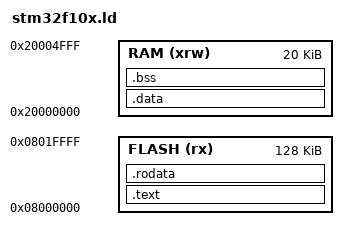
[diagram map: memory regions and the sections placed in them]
/* 指定内存区域 */
MEMORY
{
    FLASH (rx)  : ORIGIN = 0x08000000, LENGTH = 128K
    RAM (xrw)   : ORIGIN = 0x20000000, LENGTH = 20K
}

SECTIONS {

    .text      :
    {
        . = ALIGN(4);
        *start.o (.text)
        *main.o (.text)
        *(.text)
    } > FLASH

    .rodata :
    {
        . = ALIGN(4);
        *(.rodata)         /* .rodata sections (constants, strings, etc.) */
        *(.rodata*)        /* .rodata* sections (constants, strings, etc.) */
        . = ALIGN(4);
    } >FLASH

    .data : 
    {
        . = ALIGN(4);
        _sdata = .;        /* create a global symbol at data start */
        *(.data)           /* .data sections */
        *(.data*)          /* .data* sections */
        . = ALIGN(4);
        _edata = .;        /* define a global symbol at data end */
    } >RAM

    . = ALIGN(4);
    .bss :
    {
        /* This is used by the startup in order to initialize the .bss secion */
        _sbss = .;         /* define a global symbol at bss start */
        __bss_start__ = _sbss;
        *(.bss)
        *(.bss*)
        *(COMMON)

        . = ALIGN(4);
        _ebss = .;         /* define a global symbol at bss end */
        __bss_end__ = _ebss;
    } >RAM
}
